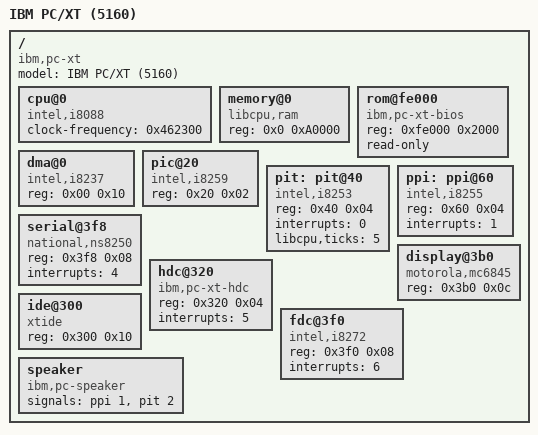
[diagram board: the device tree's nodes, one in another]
/dts-v1/;

/* IBM PC/XT (class 5160) machine description. Each device node's "compatible" names the
   hardware part; the machine builder matches it against the .device component bundles. "reg"
   gives the I/O-port base and length (the PC/XT I/O map); "interrupts" gives the IRQ line on
   the 8259. As more component bundles are written, more of these nodes bind. */

/ {
    model = "IBM PC/XT (5160)";
    compatible = "ibm,pc-xt", "ibm,5160";
    #address-cells = <1>;
    #size-cells = <1>;

    cpu@0 {
        device_type = "cpu";
        compatible = "intel,i8088";
        clock-frequency = <0x462300>;   /* 4.77 MHz */
    };

    memory@0 {
        device_type = "memory";
        compatible = "libcpu,ram";
        reg = <0x0 0xA0000>;            /* 640 KiB conventional RAM */
    };

    rom@fe000 {
        compatible = "ibm,pc-xt-bios";
        reg = <0xfe000 0x2000>;         /* 8 KiB BIOS ROM at F000:E000 */
        read-only;
    };

    dma@0 {
        compatible = "intel,i8237";
        reg = <0x00 0x10>;              /* 8237 DMA controller */
    };

    pic@20 {
        compatible = "intel,i8259";
        reg = <0x20 0x02>;              /* 8259A interrupt controller (master only on XT) */
    };

    pit: pit@40 {
        compatible = "intel,i8253";
        reg = <0x40 0x04>;              /* 8253 programmable interval timer */
        interrupts = <0>;               /* channel 0 -> IRQ0 */
        libcpu,ticks = <5>;             /* demo heartbeat: fire IRQ0 five times */
    };

    ppi: ppi@60 {
        compatible = "intel,i8255";
        reg = <0x60 0x04>;              /* 8255 PPI: keyboard + DIP switches */
        interrupts = <1>;               /* keyboard -> IRQ1 */
    };

    serial@3f8 {
        compatible = "national,ns8250";
        reg = <0x3f8 0x08>;             /* COM1 */
        interrupts = <4>;
    };

    display@3b0 {
        compatible = "motorola,mc6845", "ibm,mda";
        reg = <0x3b0 0x0c>;             /* MDA CRTC control ports (framebuffer at B0000) */
    };

    hdc@320 {
        compatible = "ibm,pc-xt-hdc", "xebec,1210";
        reg = <0x320 0x04>;             /* Xebec ST-506 fixed-disk adapter */
        interrupts = <5>;               /* hard disk -> IRQ5 */
    };

    ide@300 {
        compatible = "xtide";
        reg = <0x300 0x10>;             /* XT-IDE 8-bit ATA adapter (PIO, data high-byte latch at +8) */
    };

    fdc@3f0 {
        compatible = "intel,i8272", "nec,upd765";
        reg = <0x3f0 0x08>;             /* uPD765/8272A floppy controller */
        interrupts = <6>;               /* floppy -> IRQ6 */
    };

    speaker {
        compatible = "ibm,pc-speaker";
        /* signal-line wiring: gate/data come from 8255 port B (line 1), tone clock from
           8253 channel 2 (line 2). The phandles bind this sink to those sources explicitly. */
        signals = <&ppi 1>, <&pit 2>;
    };
};
